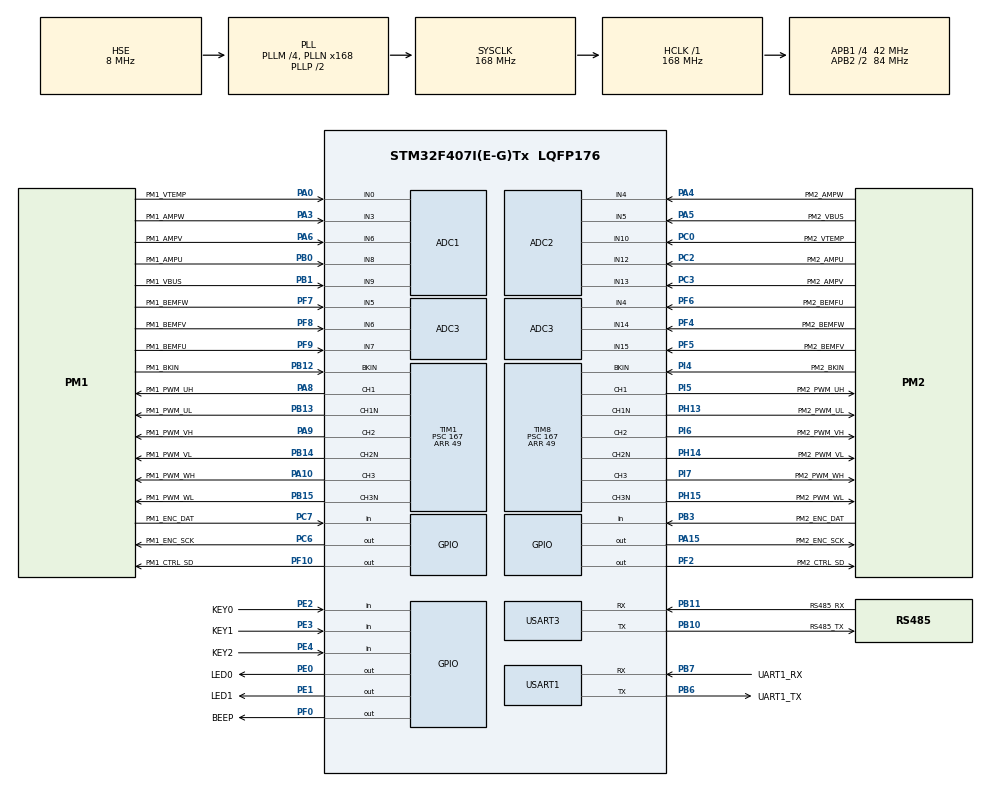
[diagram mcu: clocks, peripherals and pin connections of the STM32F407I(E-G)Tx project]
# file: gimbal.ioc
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ADC1.Channel-0\#ChannelRegularConversion=ADC_CHANNEL_0
ADC1.Channel-15\#ChannelInjectedConversion=ADC_CHANNEL_8
ADC1.Channel-16\#ChannelInjectedConversion=ADC_CHANNEL_6
ADC1.Channel-18\#ChannelInjectedConversion=ADC_CHANNEL_3
ADC1.Channel-8\#ChannelRegularConversion=ADC_CHANNEL_9
ADC1.ClockPrescaler=ADC_CLOCK_SYNC_PCLK_DIV4
ADC1.ContinuousConvMode=DISABLE
ADC1.DMAContinuousRequests=ENABLE
ADC1.EOCSelection=ADC_EOC_SEQ_CONV
ADC1.ExternalTrigConv=ADC_SOFTWARE_START
ADC1.ExternalTrigConvEdge=ADC_EXTERNALTRIGCONVEDGE_NONE
ADC1.ExternalTrigInjecConv=ADC_EXTERNALTRIGINJECCONV_T1_CC4
ADC1.InjNumberOfConversion=3
ADC1.InjectedOffset-15\#ChannelInjectedConversion=0
ADC1.InjectedOffset-16\#ChannelInjectedConversion=0
ADC1.InjectedOffset-18\#ChannelInjectedConversion=0
ADC1.InjectedRank-15\#ChannelInjectedConversion=1
ADC1.InjectedRank-16\#ChannelInjectedConversion=2
ADC1.InjectedRank-18\#ChannelInjectedConversion=3
ADC1.NbrOfConversion=2
ADC1.NbrOfConversionFlag=1
ADC1.Rank-0\#ChannelRegularConversion=1
ADC1.Rank-8\#ChannelRegularConversion=2
ADC1.SamplingTime-0\#ChannelRegularConversion=ADC_SAMPLETIME_56CYCLES
ADC1.SamplingTime-15\#ChannelInjectedConversion=ADC_SAMPLETIME_15CYCLES
ADC1.SamplingTime-16\#ChannelInjectedConversion=ADC_SAMPLETIME_15CYCLES
ADC1.SamplingTime-18\#ChannelInjectedConversion=ADC_SAMPLETIME_15CYCLES
ADC1.SamplingTime-8\#ChannelRegularConversion=ADC_SAMPLETIME_56CYCLES
ADC1.ScanConvMode=ENABLE
ADC1.master=1
ADC2.Channel-0\#ChannelRegularConversion=ADC_CHANNEL_10
ADC2.Channel-1\#ChannelRegularConversion=ADC_CHANNEL_5
ADC2.Channel-3\#ChannelInjectedConversion=ADC_CHANNEL_12
ADC2.Channel-4\#ChannelInjectedConversion=ADC_CHANNEL_13
ADC2.Channel-5\#ChannelInjectedConversion=ADC_CHANNEL_4
ADC2.ClockPrescaler=ADC_CLOCK_SYNC_PCLK_DIV4
ADC2.ContinuousConvMode=DISABLE
ADC2.DMAContinuousRequests=ENABLE
ADC2.EOCSelection=ADC_EOC_SEQ_CONV
ADC2.ExternalTrigConv=ADC_SOFTWARE_START
ADC2.ExternalTrigInjecConv=ADC_EXTERNALTRIGINJECCONV_T8_CC4
ADC2.InjNumberOfConversion=3
ADC2.InjectedOffset-3\#ChannelInjectedConversion=0
ADC2.InjectedOffset-4\#ChannelInjectedConversion=0
ADC2.InjectedOffset-5\#ChannelInjectedConversion=0
ADC2.InjectedRank-3\#ChannelInjectedConversion=1
ADC2.InjectedRank-4\#ChannelInjectedConversion=2
ADC2.InjectedRank-5\#ChannelInjectedConversion=3
ADC2.NbrOfConversion=2
ADC2.NbrOfConversionFlag=1
ADC2.Rank-0\#ChannelRegularConversion=1
ADC2.Rank-1\#ChannelRegularConversion=2
ADC2.SamplingTime-0\#ChannelRegularConversion=ADC_SAMPLETIME_56CYCLES
ADC2.SamplingTime-1\#ChannelRegularConversion=ADC_SAMPLETIME_56CYCLES
ADC2.SamplingTime-3\#ChannelInjectedConversion=ADC_SAMPLETIME_15CYCLES
ADC2.SamplingTime-4\#ChannelInjectedConversion=ADC_SAMPLETIME_15CYCLES
ADC2.SamplingTime-5\#ChannelInjectedConversion=ADC_SAMPLETIME_15CYCLES
ADC2.ScanConvMode=ENABLE
ADC3.Channel-0\#ChannelRegularConversion=ADC_CHANNEL_4
ADC3.Channel-1\#ChannelRegularConversion=ADC_CHANNEL_5
ADC3.Channel-2\#ChannelRegularConversion=ADC_CHANNEL_6
ADC3.Channel-3\#ChannelRegularConversion=ADC_CHANNEL_7
ADC3.Channel-4\#ChannelRegularConversion=ADC_CHANNEL_14
ADC3.Channel-5\#ChannelRegularConversion=ADC_CHANNEL_15
ADC3.ClockPrescaler=ADC_CLOCK_SYNC_PCLK_DIV4
ADC3.ContinuousConvMode=DISABLE
ADC3.DMAContinuousRequests=ENABLE
ADC3.EOCSelection=ADC_EOC_SEQ_CONV
ADC3.ExternalTrigConv=ADC_SOFTWARE_START
ADC3.NbrOfConversion=6
ADC3.NbrOfConversionFlag=1
ADC3.Rank-0\#ChannelRegularConversion=1
ADC3.Rank-1\#ChannelRegularConversion=2
ADC3.Rank-2\#ChannelRegularConversion=3
ADC3.Rank-3\#ChannelRegularConversion=4
ADC3.Rank-4\#ChannelRegularConversion=5
ADC3.Rank-5\#ChannelRegularConversion=6
ADC3.SamplingTime-0\#ChannelRegularConversion=ADC_SAMPLETIME_144CYCLES
ADC3.SamplingTime-1\#ChannelRegularConversion=ADC_SAMPLETIME_144CYCLES
ADC3.SamplingTime-2\#ChannelRegularConversion=ADC_SAMPLETIME_144CYCLES
ADC3.SamplingTime-3\#ChannelRegularConversion=ADC_SAMPLETIME_144CYCLES
ADC3.SamplingTime-4\#ChannelRegularConversion=ADC_SAMPLETIME_144CYCLES
ADC3.SamplingTime-5\#ChannelRegularConversion=ADC_SAMPLETIME_144CYCLES
ADC3.ScanConvMode=ENABLE
Dma.ADC1.0.Direction=DMA_PERIPH_TO_MEMORY
Dma.ADC1.0.FIFOMode=DMA_FIFOMODE_DISABLE
Dma.ADC1.0.Instance=DMA2_Stream0
Dma.ADC1.0.MemDataAlignment=DMA_MDATAALIGN_HALFWORD
Dma.ADC1.0.MemInc=DMA_MINC_ENABLE
Dma.ADC1.0.Mode=DMA_CIRCULAR
Dma.ADC1.0.PeriphDataAlignment=DMA_PDATAALIGN_HALFWORD
Dma.ADC1.0.PeriphInc=DMA_PINC_DISABLE
Dma.ADC1.0.Priority=DMA_PRIORITY_LOW
Dma.ADC2.1.Direction=DMA_PERIPH_TO_MEMORY
Dma.ADC2.1.FIFOMode=DMA_FIFOMODE_DISABLE
Dma.ADC2.1.Instance=DMA2_Stream2
Dma.ADC2.1.MemDataAlignment=DMA_MDATAALIGN_HALFWORD
Dma.ADC2.1.MemInc=DMA_MINC_ENABLE
Dma.ADC2.1.Mode=DMA_CIRCULAR
Dma.ADC2.1.PeriphDataAlignment=DMA_PDATAALIGN_HALFWORD
Dma.ADC2.1.PeriphInc=DMA_PINC_DISABLE
Dma.ADC2.1.Priority=DMA_PRIORITY_LOW
Dma.ADC3.2.Direction=DMA_PERIPH_TO_MEMORY
Dma.ADC3.2.FIFOMode=DMA_FIFOMODE_DISABLE
Dma.ADC3.2.Instance=DMA2_Stream1
Dma.ADC3.2.MemDataAlignment=DMA_MDATAALIGN_HALFWORD
Dma.ADC3.2.MemInc=DMA_MINC_ENABLE
Dma.ADC3.2.Mode=DMA_CIRCULAR
Dma.ADC3.2.PeriphDataAlignment=DMA_PDATAALIGN_HALFWORD
Dma.ADC3.2.PeriphInc=DMA_PINC_DISABLE
Dma.ADC3.2.Priority=DMA_PRIORITY_LOW
Dma.Request0=ADC1
Dma.Request1=ADC2
Dma.Request2=ADC3
Mcu.Family=STM32F4
Mcu.Name=STM32F407I(E-G)Tx
Mcu.Package=LQFP176
NVIC.ADC_IRQn=true\:0\:0\:false\:false\:true\:true\:true\:true
NVIC.PriorityGroup=NVIC_PRIORITYGROUP_4
NVIC.TIM1_TRG_COM_TIM11_IRQn=true\:0\:0\:false\:false\:true\:true\:true\:true
NVIC.TIM7_IRQn=true\:0\:0\:false\:false\:true\:true\:true\:true
NVIC.TIM8_TRG_COM_TIM14_IRQn=true\:0\:0\:false\:false\:true\:true\:true\:true
PA0-WKUP.GPIO_Label=PM1_VTEMP
PA0-WKUP.Signal=ADCx_IN0
PA10.GPIO_Label=PM1_PWM_WH
PA10.GPIO_Speed=GPIO_SPEED_FREQ_HIGH
PA10.Signal=S_TIM1_CH3
PA13.Mode=Serial_Wire
PA13.Signal=SYS_JTMS-SWDIO
PA14.Mode=Serial_Wire
PA14.Signal=SYS_JTCK-SWCLK
PA15.GPIO_Label=PM2_ENC_SCK
PA15.GPIO_PuPd=GPIO_PULLUP
PA15.GPIO_Speed=GPIO_SPEED_FREQ_VERY_HIGH
PA15.PinState=GPIO_PIN_SET
PA15.Signal=GPIO_Output
PA3.GPIO_Label=PM1_AMPW
PA3.Signal=ADCx_IN3
PA4.GPIO_Label=PM2_AMPW
PA4.Signal=ADCx_IN4
PA5.GPIO_Label=PM2_VBUS
PA5.Signal=ADCx_IN5
PA6.GPIO_Label=PM1_AMPV
PA6.Signal=ADCx_IN6
PA8.GPIO_Label=PM1_PWM_UH
PA8.GPIO_Speed=GPIO_SPEED_FREQ_HIGH
PA8.Signal=S_TIM1_CH1
PA9.GPIO_Label=PM1_PWM_VH
PA9.GPIO_Speed=GPIO_SPEED_FREQ_HIGH
PA9.Signal=S_TIM1_CH2
PB0.GPIO_Label=PM1_AMPU
PB0.Signal=ADCx_IN8
PB1.GPIO_Label=PM1_VBUS
PB1.Signal=ADCx_IN9
PB10.GPIO_Label=RS485_TX
PB10.Mode=Asynchronous
PB10.Signal=USART3_TX
PB11.GPIO_Label=RS485_RX
PB11.Mode=Asynchronous
PB11.Signal=USART3_RX
PB12.GPIO_Label=PM1_BKIN
PB12.Mode=Activate-Break-Input
PB12.Signal=TIM1_BKIN
PB13.GPIO_Label=PM1_PWM_UL
PB13.GPIO_Speed=GPIO_SPEED_FREQ_HIGH
PB13.Mode=PWM Generation1 CH1 CH1N
PB13.Signal=TIM1_CH1N
PB14.GPIO_Label=PM1_PWM_VL
PB14.GPIO_Speed=GPIO_SPEED_FREQ_HIGH
PB14.Mode=PWM Generation2 CH2 CH2N
PB14.Signal=TIM1_CH2N
PB15.GPIO_Label=PM1_PWM_WL
PB15.GPIO_Speed=GPIO_SPEED_FREQ_HIGH
PB15.Mode=PWM Generation3 CH3 CH3N
PB15.Signal=TIM1_CH3N
PB3.GPIO_Label=PM2_ENC_DAT
PB3.GPIO_PuPd=GPIO_NOPULL
PB3.Signal=GPIO_Input
PB6.GPIO_Label=UART1_TX
PB6.Mode=Asynchronous
PB6.Signal=USART1_TX
PB7.GPIO_Label=UART1_RX
PB7.Mode=Asynchronous
PB7.Signal=USART1_RX
PC0.GPIO_Label=PM2_VTEMP
PC0.Signal=ADCx_IN10
PC2.GPIO_Label=PM2_AMPU
PC2.Signal=ADCx_IN12
PC3.GPIO_Label=PM2_AMPV
PC3.Signal=ADCx_IN13
PC6.GPIO_Label=PM1_ENC_SCK
PC6.GPIO_PuPd=GPIO_PULLUP
PC6.GPIO_Speed=GPIO_SPEED_FREQ_VERY_HIGH
PC6.PinState=GPIO_PIN_SET
PC6.Signal=GPIO_Output
PC7.GPIO_Label=PM1_ENC_DAT
PC7.GPIO_PuPd=GPIO_NOPULL
PC7.Signal=GPIO_Input
PE0.GPIO_Label=LED0
PE0.GPIO_PuPd=GPIO_PULLUP
PE0.Signal=GPIO_Output
PE1.GPIO_Label=LED1
PE1.GPIO_PuPd=GPIO_PULLUP
PE1.Signal=GPIO_Output
PE2.GPIO_Label=KEY0
PE2.GPIO_PuPd=GPIO_PULLUP
PE2.Signal=GPIO_Input
PE3.GPIO_Label=KEY1
PE3.GPIO_PuPd=GPIO_PULLUP
PE3.Signal=GPIO_Input
PE4.GPIO_Label=KEY2
PE4.GPIO_PuPd=GPIO_PULLUP
PE4.Signal=GPIO_Input
PF0.GPIO_Label=BEEP
PF0.GPIO_PuPd=GPIO_PULLDOWN
PF0.Signal=GPIO_Output
PF10.GPIO_Label=PM1_CTRL_SD
PF10.GPIO_PuPd=GPIO_PULLUP
PF10.GPIO_Speed=GPIO_SPEED_FREQ_LOW
PF10.Signal=GPIO_Output
PF2.GPIO_Label=PM2_CTRL_SD
PF2.GPIO_PuPd=GPIO_PULLUP
PF2.GPIO_Speed=GPIO_SPEED_FREQ_LOW
PF2.Signal=GPIO_Output
PF4.GPIO_Label=PM2_BEMFW
PF4.Mode=IN14
PF4.Signal=ADC3_IN14
PF5.GPIO_Label=PM2_BEMFV
PF5.Mode=IN15
PF5.Signal=ADC3_IN15
PF6.GPIO_Label=PM2_BEMFU
PF6.Mode=IN4
PF6.Signal=ADC3_IN4
PF7.GPIO_Label=PM1_BEMFW
PF7.Mode=IN5
PF7.Signal=ADC3_IN5
PF8.GPIO_Label=PM1_BEMFV
PF8.Mode=IN6
PF8.Signal=ADC3_IN6
PF9.GPIO_Label=PM1_BEMFU
PF9.Mode=IN7
PF9.Signal=ADC3_IN7
PH0-OSC_IN.Mode=HSE-External-Oscillator
PH0-OSC_IN.Signal=RCC_OSC_IN
PH1-OSC_OUT.Mode=HSE-External-Oscillator
PH1-OSC_OUT.Signal=RCC_OSC_OUT
PH13.GPIO_Label=PM2_PWM_UL
PH13.Mode=PWM Generation1 CH1 CH1N
PH13.Signal=TIM8_CH1N
PH14.GPIO_Label=PM2_PWM_VL
PH14.Mode=PWM Generation2 CH2 CH2N
PH14.Signal=TIM8_CH2N
PH15.GPIO_Label=PM2_PWM_WL
PH15.Mode=PWM Generation3 CH3 CH3N
PH15.Signal=TIM8_CH3N
PI4.GPIO_Label=PM2_BKIN
PI4.Mode=Activate-Break-Input
PI4.Signal=TIM8_BKIN
PI5.GPIO_Label=PM2_PWM_UH
PI5.Signal=S_TIM8_CH1
PI6.GPIO_Label=PM2_PWM_VH
PI6.Signal=S_TIM8_CH2
PI7.GPIO_Label=PM2_PWM_WH
PI7.Signal=S_TIM8_CH3
ProjectManager.HeapSize=0x200
ProjectManager.StackSize=0x400
ProjectManager.TargetToolchain=CMake
RCC.48MHZClocksFreq_Value=84000000
RCC.AHBFreq_Value=168000000
RCC.APB1CLKDivider=RCC_HCLK_DIV4
RCC.APB1Freq_Value=42000000
RCC.APB1TimFreq_Value=84000000
RCC.APB2CLKDivider=RCC_HCLK_DIV2
RCC.APB2Freq_Value=84000000
RCC.APB2TimFreq_Value=168000000
RCC.CortexFreq_Value=168000000
RCC.HCLKFreq_Value=168000000
RCC.HSE_VALUE=8000000
RCC.HSI_VALUE=16000000
RCC.LSE_VALUE=32768
RCC.PLLM=4
RCC.PLLN=168
RCC.PLLSourceVirtual=RCC_PLLSOURCE_HSE
RCC.SYSCLKFreq_VALUE=168000000
RCC.SYSCLKSource=RCC_SYSCLKSOURCE_PLLCLK
RCC.VCOOutputFreq_Value=336000000
SH.ADCx_IN0.0=ADC1_IN0,IN0
SH.ADCx_IN10.0=ADC2_IN10,IN10
SH.ADCx_IN12.0=ADC2_IN12,IN12
SH.ADCx_IN13.0=ADC2_IN13,IN13
SH.ADCx_IN3.0=ADC1_IN3,IN3
SH.ADCx_IN4.0=ADC2_IN4,IN4
SH.ADCx_IN5.0=ADC2_IN5,IN5
SH.ADCx_IN6.0=ADC1_IN6,IN6
SH.ADCx_IN8.0=ADC1_IN8,IN8
SH.ADCx_IN9.0=ADC1_IN9,IN9
SH.S_TIM1_CH1.0=TIM1_CH1,PWM Generation1 CH1 CH1N
SH.S_TIM1_CH2.0=TIM1_CH2,PWM Generation2 CH2 CH2N
SH.S_TIM1_CH3.0=TIM1_CH3,PWM Generation3 CH3 CH3N
SH.S_TIM8_CH1.0=TIM8_CH1,PWM Generation1 CH1 CH1N
SH.S_TIM8_CH2.0=TIM8_CH2,PWM Generation2 CH2 CH2N
SH.S_TIM8_CH3.0=TIM8_CH3,PWM Generation3 CH3 CH3N
TIM1.AutoReloadPreload=TIM_AUTORELOAD_PRELOAD_ENABLE
TIM1.AutomaticOutput=TIM_AUTOMATICOUTPUT_DISABLE
TIM1.Channel-Output\ Compare4\ No\ Output=TIM_CHANNEL_4
TIM1.Channel-PWM\ Generation1\ CH1\ CH1N=TIM_CHANNEL_1
TIM1.Channel-PWM\ Generation2\ CH2\ CH2N=TIM_CHANNEL_2
TIM1.Channel-PWM\ Generation3\ CH3\ CH3N=TIM_CHANNEL_3
TIM1.CounterMode=TIM_COUNTERMODE_CENTERALIGNED1
TIM1.DeadTime=100
TIM1.LockLevel=TIM_LOCKLEVEL_OFF
TIM1.OCMode_4=TIM_OCMODE_ACTIVE
TIM1.OCMode_PWM-PWM\ Generation1\ CH1\ CH1N=TIM_OCMODE_PWM2
TIM1.OCMode_PWM-PWM\ Generation2\ CH2\ CH2N=TIM_OCMODE_PWM2
TIM1.OCMode_PWM-PWM\ Generation3\ CH3\ CH3N=TIM_OCMODE_PWM2
TIM1.OCNIdleState_2=TIM_OCNIDLESTATE_RESET
TIM1.OffStateIDLEMode=TIM_OSSI_DISABLE
TIM1.OffStateRunMode=TIM_OSSR_DISABLE
TIM1.Period=49
TIM1.Prescaler=167
TIM1.Pulse-Output\ Compare4\ No\ Output=45
TIM1.Pulse-PWM\ Generation1\ CH1\ CH1N=0
TIM1.Pulse-PWM\ Generation2\ CH2\ CH2N=0
TIM1.RepetitionCounter=1
TIM1.TIM_MasterOutputTrigger=TIM_TRGO_OC4REF
TIM1.TIM_MasterSlaveMode=TIM_MASTERSLAVEMODE_DISABLE
TIM6.AutoReloadPreload=TIM_AUTORELOAD_PRELOAD_ENABLE
TIM6.Period=100-1
TIM6.Prescaler=84-1
TIM7.AutoReloadPreload=TIM_AUTORELOAD_PRELOAD_ENABLE
TIM7.Period=100-1
TIM7.Prescaler=84-1
TIM8.AutoReloadPreload=TIM_AUTORELOAD_PRELOAD_ENABLE
TIM8.AutomaticOutput=TIM_AUTOMATICOUTPUT_DISABLE
TIM8.Channel-Output\ Compare4\ No\ Output=TIM_CHANNEL_4
TIM8.Channel-PWM\ Generation1\ CH1\ CH1N=TIM_CHANNEL_1
TIM8.Channel-PWM\ Generation2\ CH2\ CH2N=TIM_CHANNEL_2
TIM8.Channel-PWM\ Generation3\ CH3\ CH3N=TIM_CHANNEL_3
TIM8.CounterMode=TIM_COUNTERMODE_CENTERALIGNED1
TIM8.DeadTime=100
TIM8.OCMode_4=TIM_OCMODE_ACTIVE
TIM8.OCMode_PWM-PWM\ Generation1\ CH1\ CH1N=TIM_OCMODE_PWM2
TIM8.OCMode_PWM-PWM\ Generation2\ CH2\ CH2N=TIM_OCMODE_PWM2
TIM8.OCMode_PWM-PWM\ Generation3\ CH3\ CH3N=TIM_OCMODE_PWM2
TIM8.OffStateIDLEMode=TIM_OSSI_DISABLE
TIM8.OffStateRunMode=TIM_OSSR_DISABLE
TIM8.Period=49
TIM8.Prescaler=167
TIM8.Pulse-Output\ Compare4\ No\ Output=45
TIM8.RepetitionCounter=1
TIM8.TIM_MasterOutputTrigger=TIM_TRGO_OC4REF
USART1.VirtualMode=VM_ASYNC
USART3.VirtualMode=VM_ASYNC
VP_CRC_VS_CRC.Mode=CRC_Activate
VP_TIM1_VS_ClockSourceINT.Mode=Internal
VP_TIM1_VS_no_output4.Mode=Output Compare4 No Output
VP_TIM6_VS_ClockSourceINT.Mode=Enable_Timer
VP_TIM7_VS_ClockSourceINT.Mode=Enable_Timer
VP_TIM8_VS_ClockSourceINT.Mode=Internal
VP_TIM8_VS_no_output4.Mode=Output Compare4 No Output
board=custom

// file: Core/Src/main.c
/* USER CODE BEGIN Header */
/**
  ******************************************************************************
  * @file           : main.c
  * @brief          : Main program body
  ******************************************************************************
  * @attention
  *
  * Copyright (c) 2026 STMicroelectronics.
  * All rights reserved.
  *
  * This software is licensed under terms that can be found in the LICENSE file
  * in the root directory of this software component.
  * If no LICENSE file comes with this software, it is provided AS-IS.
  *
  ******************************************************************************
  */
/* USER CODE END Header */
#include "main.h"

/* USER CODE BEGIN Includes */
#include "app.h"
#include "foc.h"
#include "control.h"
#include "biss.h"
/* USER CODE END Includes */

ADC_HandleTypeDef hadc1;
ADC_HandleTypeDef hadc2;
ADC_HandleTypeDef hadc3;
DMA_HandleTypeDef hdma_adc1;
DMA_HandleTypeDef hdma_adc2;
DMA_HandleTypeDef hdma_adc3;

CRC_HandleTypeDef hcrc;

TIM_HandleTypeDef htim1;
TIM_HandleTypeDef htim6;
TIM_HandleTypeDef htim7;
TIM_HandleTypeDef htim8;

UART_HandleTypeDef huart1;
UART_HandleTypeDef huart3;

void SystemClock_Config(void);
static void MX_GPIO_Init(void);
static void MX_DMA_Init(void);
static void MX_USART1_UART_Init(void);
static void MX_ADC1_Init(void);
static void MX_ADC2_Init(void);
static void MX_ADC3_Init(void);
static void MX_TIM1_Init(void);
static void MX_TIM8_Init(void);
static void MX_USART3_UART_Init(void);
static void MX_TIM7_Init(void);
static void MX_TIM6_Init(void);
static void MX_CRC_Init(void);
/* USER CODE BEGIN PFP */
uint8_t KEY_Scan(uint16_t GPIO_Pin);  /************************** LED***********************/

/* USER CODE END PFP */

int main(void)
{

  /* MCU Configuration--------------------------------------------------------*/

  /* Reset of all peripherals, Initializes the Flash interface and the Systick. */
  HAL_Init();

  /* Configure the system clock */
  SystemClock_Config();

  /* Initialize all configured peripherals */
  MX_GPIO_Init();
  MX_DMA_Init();
  MX_USART1_UART_Init();
  MX_ADC1_Init();
  MX_ADC2_Init();
  MX_ADC3_Init();
  MX_TIM1_Init();
  MX_TIM8_Init();
  MX_USART3_UART_Init();
  MX_TIM7_Init();
  MX_TIM6_Init();
  MX_CRC_Init();
  /* USER CODE BEGIN 2 */

  Motor_Init();
  setup();

//  SVPWM_OpenLoop_Example();

  /* USER CODE END 2 */

  /* Infinite loop */
  while (1)
  {

    /* USER CODE BEGIN 3 */

    motor1.theta_m =MP55_ReadFrame(&encoder_motor1);        // 编码器数据（机械角度）

  }
  /* USER CODE END 3 */
}

void SystemClock_Config(void)
{
  RCC_OscInitTypeDef RCC_OscInitStruct = {0};
  RCC_ClkInitTypeDef RCC_ClkInitStruct = {0};

  /** Configure the main internal regulator output voltage
  */
  __HAL_RCC_PWR_CLK_ENABLE();
  __HAL_PWR_VOLTAGESCALING_CONFIG(PWR_REGULATOR_VOLTAGE_SCALE1);

  /** Initializes the RCC Oscillators according to the specified parameters
  * in the RCC_OscInitTypeDef structure.
  */
  RCC_OscInitStruct.OscillatorType = RCC_OSCILLATORTYPE_HSE;
  RCC_OscInitStruct.HSEState = RCC_HSE_ON;
  RCC_OscInitStruct.PLL.PLLState = RCC_PLL_ON;
  RCC_OscInitStruct.PLL.PLLSource = RCC_PLLSOURCE_HSE;
  RCC_OscInitStruct.PLL.PLLM = 4;
  RCC_OscInitStruct.PLL.PLLN = 168;
  RCC_OscInitStruct.PLL.PLLP = RCC_PLLP_DIV2;
  RCC_OscInitStruct.PLL.PLLQ = 4;
  if (HAL_RCC_OscConfig(&RCC_OscInitStruct) != HAL_OK)
  {
    Error_Handler();
  }

  /** Initializes the CPU, AHB and APB buses clocks
  */
  RCC_ClkInitStruct.ClockType = RCC_CLOCKTYPE_HCLK|RCC_CLOCKTYPE_SYSCLK
                              |RCC_CLOCKTYPE_PCLK1|RCC_CLOCKTYPE_PCLK2;
  RCC_ClkInitStruct.SYSCLKSource = RCC_SYSCLKSOURCE_PLLCLK;
  RCC_ClkInitStruct.AHBCLKDivider = RCC_SYSCLK_DIV1;
  RCC_ClkInitStruct.APB1CLKDivider = RCC_HCLK_DIV4;
  RCC_ClkInitStruct.APB2CLKDivider = RCC_HCLK_DIV2;

  if (HAL_RCC_ClockConfig(&RCC_ClkInitStruct, FLASH_LATENCY_5) != HAL_OK)
  {
    Error_Handler();
  }
}

static void MX_ADC1_Init(void)
{

  ADC_ChannelConfTypeDef sConfig = {0};
  ADC_InjectionConfTypeDef sConfigInjected = {0};

  /** Configure the global features of the ADC (Clock, Resolution, Data Alignment and number of conversion)
  */
  hadc1.Instance = ADC1;
  hadc1.Init.ClockPrescaler = ADC_CLOCK_SYNC_PCLK_DIV4;
  hadc1.Init.Resolution = ADC_RESOLUTION_12B;
  hadc1.Init.ScanConvMode = ENABLE;
  hadc1.Init.ContinuousConvMode = DISABLE;
  hadc1.Init.DiscontinuousConvMode = DISABLE;
  hadc1.Init.ExternalTrigConvEdge = ADC_EXTERNALTRIGCONVEDGE_NONE;
  hadc1.Init.ExternalTrigConv = ADC_SOFTWARE_START;
  hadc1.Init.DataAlign = ADC_DATAALIGN_RIGHT;
  hadc1.Init.NbrOfConversion = 2;
  hadc1.Init.DMAContinuousRequests = ENABLE;
  hadc1.Init.EOCSelection = ADC_EOC_SEQ_CONV;
  if (HAL_ADC_Init(&hadc1) != HAL_OK)
  {
    Error_Handler();
  }

  /** Configure for the selected ADC regular channel its corresponding rank in the sequencer and its sample time.
  */
  sConfig.Channel = ADC_CHANNEL_0;
  sConfig.Rank = 1;
  sConfig.SamplingTime = ADC_SAMPLETIME_56CYCLES;
  if (HAL_ADC_ConfigChannel(&hadc1, &sConfig) != HAL_OK)
  {
    Error_Handler();
  }

  /** Configure for the selected ADC regular channel its corresponding rank in the sequencer and its sample time.
  */
  sConfig.Channel = ADC_CHANNEL_9;
  sConfig.Rank = 2;
  if (HAL_ADC_ConfigChannel(&hadc1, &sConfig) != HAL_OK)
  {
    Error_Handler();
  }

  /** Configures for the selected ADC injected channel its corresponding rank in the sequencer and its sample time
  */
  sConfigInjected.InjectedChannel = ADC_CHANNEL_8;
  sConfigInjected.InjectedRank = 1;
  sConfigInjected.InjectedNbrOfConversion = 3;
  sConfigInjected.InjectedSamplingTime = ADC_SAMPLETIME_15CYCLES;
  sConfigInjected.ExternalTrigInjecConvEdge = ADC_EXTERNALTRIGINJECCONVEDGE_RISING;
  sConfigInjected.ExternalTrigInjecConv = ADC_EXTERNALTRIGINJECCONV_T1_CC4;
  sConfigInjected.AutoInjectedConv = DISABLE;
  sConfigInjected.InjectedDiscontinuousConvMode = DISABLE;
  sConfigInjected.InjectedOffset = 0;
  if (HAL_ADCEx_InjectedConfigChannel(&hadc1, &sConfigInjected) != HAL_OK)
  {
    Error_Handler();
  }

  /** Configures for the selected ADC injected channel its corresponding rank in the sequencer and its sample time
  */
  sConfigInjected.InjectedChannel = ADC_CHANNEL_6;
  sConfigInjected.InjectedRank = 2;
  if (HAL_ADCEx_InjectedConfigChannel(&hadc1, &sConfigInjected) != HAL_OK)
  {
    Error_Handler();
  }

  /** Configures for the selected ADC injected channel its corresponding rank in the sequencer and its sample time
  */
  sConfigInjected.InjectedChannel = ADC_CHANNEL_3;
  sConfigInjected.InjectedRank = 3;
  if (HAL_ADCEx_InjectedConfigChannel(&hadc1, &sConfigInjected) != HAL_OK)
  {
    Error_Handler();
  }

}

static void MX_ADC2_Init(void)
{

  ADC_ChannelConfTypeDef sConfig = {0};
  ADC_InjectionConfTypeDef sConfigInjected = {0};

  /** Configure the global features of the ADC (Clock, Resolution, Data Alignment and number of conversion)
  */
  hadc2.Instance = ADC2;
  hadc2.Init.ClockPrescaler = ADC_CLOCK_SYNC_PCLK_DIV4;
  hadc2.Init.Resolution = ADC_RESOLUTION_12B;
  hadc2.Init.ScanConvMode = ENABLE;
  hadc2.Init.ContinuousConvMode = DISABLE;
  hadc2.Init.DiscontinuousConvMode = DISABLE;
  hadc2.Init.ExternalTrigConvEdge = ADC_EXTERNALTRIGCONVEDGE_NONE;
  hadc2.Init.ExternalTrigConv = ADC_SOFTWARE_START;
  hadc2.Init.DataAlign = ADC_DATAALIGN_RIGHT;
  hadc2.Init.NbrOfConversion = 2;
  hadc2.Init.DMAContinuousRequests = ENABLE;
  hadc2.Init.EOCSelection = ADC_EOC_SEQ_CONV;
  if (HAL_ADC_Init(&hadc2) != HAL_OK)
  {
    Error_Handler();
  }

  /** Configure for the selected ADC regular channel its corresponding rank in the sequencer and its sample time.
  */
  sConfig.Channel = ADC_CHANNEL_10;
  sConfig.Rank = 1;
  sConfig.SamplingTime = ADC_SAMPLETIME_56CYCLES;
  if (HAL_ADC_ConfigChannel(&hadc2, &sConfig) != HAL_OK)
  {
    Error_Handler();
  }

  /** Configure for the selected ADC regular channel its corresponding rank in the sequencer and its sample time.
  */
  sConfig.Channel = ADC_CHANNEL_5;
  sConfig.Rank = 2;
  if (HAL_ADC_ConfigChannel(&hadc2, &sConfig) != HAL_OK)
  {
    Error_Handler();
  }

  /** Configures for the selected ADC injected channel its corresponding rank in the sequencer and its sample time
  */
  sConfigInjected.InjectedChannel = ADC_CHANNEL_12;
  sConfigInjected.InjectedRank = 1;
  sConfigInjected.InjectedNbrOfConversion = 3;
  sConfigInjected.InjectedSamplingTime = ADC_SAMPLETIME_15CYCLES;
  sConfigInjected.ExternalTrigInjecConvEdge = ADC_EXTERNALTRIGINJECCONVEDGE_RISING;
  sConfigInjected.ExternalTrigInjecConv = ADC_EXTERNALTRIGINJECCONV_T8_CC4;
  sConfigInjected.AutoInjectedConv = DISABLE;
  sConfigInjected.InjectedDiscontinuousConvMode = DISABLE;
  sConfigInjected.InjectedOffset = 0;
  if (HAL_ADCEx_InjectedConfigChannel(&hadc2, &sConfigInjected) != HAL_OK)
  {
    Error_Handler();
  }

  /** Configures for the selected ADC injected channel its corresponding rank in the sequencer and its sample time
  */
  sConfigInjected.InjectedChannel = ADC_CHANNEL_13;
  sConfigInjected.InjectedRank = 2;
  if (HAL_ADCEx_InjectedConfigChannel(&hadc2, &sConfigInjected) != HAL_OK)
  {
    Error_Handler();
  }

  /** Configures for the selected ADC injected channel its corresponding rank in the sequencer and its sample time
  */
  sConfigInjected.InjectedChannel = ADC_CHANNEL_4;
  sConfigInjected.InjectedRank = 3;
  if (HAL_ADCEx_InjectedConfigChannel(&hadc2, &sConfigInjected) != HAL_OK)
  {
    Error_Handler();
  }

}

static void MX_ADC3_Init(void)
{

  ADC_ChannelConfTypeDef sConfig = {0};

  /** Configure the global features of the ADC (Clock, Resolution, Data Alignment and number of conversion)
  */
  hadc3.Instance = ADC3;
  hadc3.Init.ClockPrescaler = ADC_CLOCK_SYNC_PCLK_DIV4;
  hadc3.Init.Resolution = ADC_RESOLUTION_12B;
  hadc3.Init.ScanConvMode = ENABLE;
  hadc3.Init.ContinuousConvMode = DISABLE;
  hadc3.Init.DiscontinuousConvMode = DISABLE;
  hadc3.Init.ExternalTrigConvEdge = ADC_EXTERNALTRIGCONVEDGE_NONE;
  hadc3.Init.ExternalTrigConv = ADC_SOFTWARE_START;
  hadc3.Init.DataAlign = ADC_DATAALIGN_RIGHT;
  hadc3.Init.NbrOfConversion = 6;
  hadc3.Init.DMAContinuousRequests = ENABLE;
  hadc3.Init.EOCSelection = ADC_EOC_SEQ_CONV;
  if (HAL_ADC_Init(&hadc3) != HAL_OK)
  {
    Error_Handler();
  }

  /** Configure for the selected ADC regular channel its corresponding rank in the sequencer and its sample time.
  */
  sConfig.Channel = ADC_CHANNEL_4;
  sConfig.Rank = 1;
  sConfig.SamplingTime = ADC_SAMPLETIME_144CYCLES;
  if (HAL_ADC_ConfigChannel(&hadc3, &sConfig) != HAL_OK)
  {
    Error_Handler();
  }

  /** Configure for the selected ADC regular channel its corresponding rank in the sequencer and its sample time.
  */
  sConfig.Channel = ADC_CHANNEL_5;
  sConfig.Rank = 2;
  if (HAL_ADC_ConfigChannel(&hadc3, &sConfig) != HAL_OK)
  {
    Error_Handler();
  }

  /** Configure for the selected ADC regular channel its corresponding rank in the sequencer and its sample time.
  */
  sConfig.Channel = ADC_CHANNEL_6;
  sConfig.Rank = 3;
  if (HAL_ADC_ConfigChannel(&hadc3, &sConfig) != HAL_OK)
  {
    Error_Handler();
  }

  /** Configure for the selected ADC regular channel its corresponding rank in the sequencer and its sample time.
  */
  sConfig.Channel = ADC_CHANNEL_7;
  sConfig.Rank = 4;
  if (HAL_ADC_ConfigChannel(&hadc3, &sConfig) != HAL_OK)
  {
    Error_Handler();
  }

  /** Configure for the selected ADC regular channel its corresponding rank in the sequencer and its sample time.
  */
  sConfig.Channel = ADC_CHANNEL_14;
  sConfig.Rank = 5;
  if (HAL_ADC_ConfigChannel(&hadc3, &sConfig) != HAL_OK)
  {
    Error_Handler();
  }

  /** Configure for the selected ADC regular channel its corresponding rank in the sequencer and its sample time.
  */
  sConfig.Channel = ADC_CHANNEL_15;
  sConfig.Rank = 6;
  if (HAL_ADC_ConfigChannel(&hadc3, &sConfig) != HAL_OK)
  {
    Error_Handler();
  }

}

static void MX_CRC_Init(void)
{

  hcrc.Instance = CRC;
  if (HAL_CRC_Init(&hcrc) != HAL_OK)
  {
    Error_Handler();
  }

}

static void MX_TIM1_Init(void)
{

  TIM_ClockConfigTypeDef sClockSourceConfig = {0};
  TIM_MasterConfigTypeDef sMasterConfig = {0};
  TIM_OC_InitTypeDef sConfigOC = {0};
  TIM_BreakDeadTimeConfigTypeDef sBreakDeadTimeConfig = {0};

  htim1.Instance = TIM1;
  htim1.Init.Prescaler = 167;
  htim1.Init.CounterMode = TIM_COUNTERMODE_CENTERALIGNED1;
  htim1.Init.Period = 49;
  htim1.Init.ClockDivision = TIM_CLOCKDIVISION_DIV1;
  htim1.Init.RepetitionCounter = 1;
  htim1.Init.AutoReloadPreload = TIM_AUTORELOAD_PRELOAD_ENABLE;
  if (HAL_TIM_Base_Init(&htim1) != HAL_OK)
  {
    Error_Handler();
  }
  sClockSourceConfig.ClockSource = TIM_CLOCKSOURCE_INTERNAL;
  if (HAL_TIM_ConfigClockSource(&htim1, &sClockSourceConfig) != HAL_OK)
  {
    Error_Handler();
  }
  if (HAL_TIM_PWM_Init(&htim1) != HAL_OK)
  {
    Error_Handler();
  }
  if (HAL_TIM_OC_Init(&htim1) != HAL_OK)
  {
    Error_Handler();
  }
  sMasterConfig.MasterOutputTrigger = TIM_TRGO_OC4REF;
  sMasterConfig.MasterSlaveMode = TIM_MASTERSLAVEMODE_DISABLE;
  if (HAL_TIMEx_MasterConfigSynchronization(&htim1, &sMasterConfig) != HAL_OK)
  {
    Error_Handler();
  }
  sConfigOC.OCMode = TIM_OCMODE_PWM2;
  sConfigOC.Pulse = 0;
  sConfigOC.OCPolarity = TIM_OCPOLARITY_HIGH;
  sConfigOC.OCNPolarity = TIM_OCNPOLARITY_HIGH;
  sConfigOC.OCFastMode = TIM_OCFAST_DISABLE;
  sConfigOC.OCIdleState = TIM_OCIDLESTATE_RESET;
  sConfigOC.OCNIdleState = TIM_OCNIDLESTATE_RESET;
  if (HAL_TIM_PWM_ConfigChannel(&htim1, &sConfigOC, TIM_CHANNEL_1) != HAL_OK)
  {
    Error_Handler();
  }
  if (HAL_TIM_PWM_ConfigChannel(&htim1, &sConfigOC, TIM_CHANNEL_2) != HAL_OK)
  {
    Error_Handler();
  }
  if (HAL_TIM_PWM_ConfigChannel(&htim1, &sConfigOC, TIM_CHANNEL_3) != HAL_OK)
  {
    Error_Handler();
  }
  sConfigOC.OCMode = TIM_OCMODE_ACTIVE;
  sConfigOC.Pulse = 45;
  if (HAL_TIM_OC_ConfigChannel(&htim1, &sConfigOC, TIM_CHANNEL_4) != HAL_OK)
  {
    Error_Handler();
  }
  sBreakDeadTimeConfig.OffStateRunMode = TIM_OSSR_DISABLE;
  sBreakDeadTimeConfig.OffStateIDLEMode = TIM_OSSI_DISABLE;
  sBreakDeadTimeConfig.LockLevel = TIM_LOCKLEVEL_OFF;
  sBreakDeadTimeConfig.DeadTime = 100;
  sBreakDeadTimeConfig.BreakState = TIM_BREAK_ENABLE;
  sBreakDeadTimeConfig.BreakPolarity = TIM_BREAKPOLARITY_HIGH;
  sBreakDeadTimeConfig.AutomaticOutput = TIM_AUTOMATICOUTPUT_DISABLE;
  if (HAL_TIMEx_ConfigBreakDeadTime(&htim1, &sBreakDeadTimeConfig) != HAL_OK)
  {
    Error_Handler();
  }
  HAL_TIM_MspPostInit(&htim1);

}

static void MX_TIM6_Init(void)
{

  TIM_MasterConfigTypeDef sMasterConfig = {0};

  htim6.Instance = TIM6;
  htim6.Init.Prescaler = 84-1;
  htim6.Init.CounterMode = TIM_COUNTERMODE_UP;
  htim6.Init.Period = 100-1;
  htim6.Init.AutoReloadPreload = TIM_AUTORELOAD_PRELOAD_ENABLE;
  if (HAL_TIM_Base_Init(&htim6) != HAL_OK)
  {
    Error_Handler();
  }
  sMasterConfig.MasterOutputTrigger = TIM_TRGO_RESET;
  sMasterConfig.MasterSlaveMode = TIM_MASTERSLAVEMODE_DISABLE;
  if (HAL_TIMEx_MasterConfigSynchronization(&htim6, &sMasterConfig) != HAL_OK)
  {
    Error_Handler();
  }

}

static void MX_TIM7_Init(void)
{

  TIM_MasterConfigTypeDef sMasterConfig = {0};

  htim7.Instance = TIM7;
  htim7.Init.Prescaler = 84-1;
  htim7.Init.CounterMode = TIM_COUNTERMODE_UP;
  htim7.Init.Period = 100-1;
  htim7.Init.AutoReloadPreload = TIM_AUTORELOAD_PRELOAD_ENABLE;
  if (HAL_TIM_Base_Init(&htim7) != HAL_OK)
  {
    Error_Handler();
  }
  sMasterConfig.MasterOutputTrigger = TIM_TRGO_RESET;
  sMasterConfig.MasterSlaveMode = TIM_MASTERSLAVEMODE_DISABLE;
  if (HAL_TIMEx_MasterConfigSynchronization(&htim7, &sMasterConfig) != HAL_OK)
  {
    Error_Handler();
  }

}

static void MX_TIM8_Init(void)
{

  TIM_ClockConfigTypeDef sClockSourceConfig = {0};
  TIM_MasterConfigTypeDef sMasterConfig = {0};
  TIM_OC_InitTypeDef sConfigOC = {0};
  TIM_BreakDeadTimeConfigTypeDef sBreakDeadTimeConfig = {0};

  htim8.Instance = TIM8;
  htim8.Init.Prescaler = 167;
  htim8.Init.CounterMode = TIM_COUNTERMODE_CENTERALIGNED1;
  htim8.Init.Period = 49;
  htim8.Init.ClockDivision = TIM_CLOCKDIVISION_DIV1;
  htim8.Init.RepetitionCounter = 1;
  htim8.Init.AutoReloadPreload = TIM_AUTORELOAD_PRELOAD_ENABLE;
  if (HAL_TIM_Base_Init(&htim8) != HAL_OK)
  {
    Error_Handler();
  }
  sClockSourceConfig.ClockSource = TIM_CLOCKSOURCE_INTERNAL;
  if (HAL_TIM_ConfigClockSource(&htim8, &sClockSourceConfig) != HAL_OK)
  {
    Error_Handler();
  }
  if (HAL_TIM_PWM_Init(&htim8) != HAL_OK)
  {
    Error_Handler();
  }
  if (HAL_TIM_OC_Init(&htim8) != HAL_OK)
  {
    Error_Handler();
  }
  sMasterConfig.MasterOutputTrigger = TIM_TRGO_OC4REF;
  sMasterConfig.MasterSlaveMode = TIM_MASTERSLAVEMODE_DISABLE;
  if (HAL_TIMEx_MasterConfigSynchronization(&htim8, &sMasterConfig) != HAL_OK)
  {
    Error_Handler();
  }
  sConfigOC.OCMode = TIM_OCMODE_PWM2;
  sConfigOC.Pulse = 0;
  sConfigOC.OCPolarity = TIM_OCPOLARITY_HIGH;
  sConfigOC.OCNPolarity = TIM_OCNPOLARITY_HIGH;
  sConfigOC.OCFastMode = TIM_OCFAST_DISABLE;
  sConfigOC.OCIdleState = TIM_OCIDLESTATE_RESET;
  sConfigOC.OCNIdleState = TIM_OCNIDLESTATE_RESET;
  if (HAL_TIM_PWM_ConfigChannel(&htim8, &sConfigOC, TIM_CHANNEL_1) != HAL_OK)
  {
    Error_Handler();
  }
  if (HAL_TIM_PWM_ConfigChannel(&htim8, &sConfigOC, TIM_CHANNEL_2) != HAL_OK)
  {
    Error_Handler();
  }
  if (HAL_TIM_PWM_ConfigChannel(&htim8, &sConfigOC, TIM_CHANNEL_3) != HAL_OK)
  {
    Error_Handler();
  }
  sConfigOC.OCMode = TIM_OCMODE_ACTIVE;
  sConfigOC.Pulse = 45;
  if (HAL_TIM_OC_ConfigChannel(&htim8, &sConfigOC, TIM_CHANNEL_4) != HAL_OK)
  {
    Error_Handler();
  }
  sBreakDeadTimeConfig.OffStateRunMode = TIM_OSSR_DISABLE;
  sBreakDeadTimeConfig.OffStateIDLEMode = TIM_OSSI_DISABLE;
  sBreakDeadTimeConfig.LockLevel = TIM_LOCKLEVEL_OFF;
  sBreakDeadTimeConfig.DeadTime = 100;
  sBreakDeadTimeConfig.BreakState = TIM_BREAK_ENABLE;
  sBreakDeadTimeConfig.BreakPolarity = TIM_BREAKPOLARITY_HIGH;
  sBreakDeadTimeConfig.AutomaticOutput = TIM_AUTOMATICOUTPUT_DISABLE;
  if (HAL_TIMEx_ConfigBreakDeadTime(&htim8, &sBreakDeadTimeConfig) != HAL_OK)
  {
    Error_Handler();
  }
  HAL_TIM_MspPostInit(&htim8);

}

static void MX_USART1_UART_Init(void)
{

  huart1.Instance = USART1;
  huart1.Init.BaudRate = 115200;
  huart1.Init.WordLength = UART_WORDLENGTH_8B;
  huart1.Init.StopBits = UART_STOPBITS_1;
  huart1.Init.Parity = UART_PARITY_NONE;
  huart1.Init.Mode = UART_MODE_TX_RX;
  huart1.Init.HwFlowCtl = UART_HWCONTROL_NONE;
  huart1.Init.OverSampling = UART_OVERSAMPLING_16;
  if (HAL_UART_Init(&huart1) != HAL_OK)
  {
    Error_Handler();
  }

}

static void MX_USART3_UART_Init(void)
{

  huart3.Instance = USART3;
  huart3.Init.BaudRate = 115200;
  huart3.Init.WordLength = UART_WORDLENGTH_8B;
  huart3.Init.StopBits = UART_STOPBITS_1;
  huart3.Init.Parity = UART_PARITY_NONE;
  huart3.Init.Mode = UART_MODE_TX_RX;
  huart3.Init.HwFlowCtl = UART_HWCONTROL_NONE;
  huart3.Init.OverSampling = UART_OVERSAMPLING_16;
  if (HAL_UART_Init(&huart3) != HAL_OK)
  {
    Error_Handler();
  }

}

static void MX_DMA_Init(void)
{

  /* DMA controller clock enable */
  __HAL_RCC_DMA2_CLK_ENABLE();

}

static void MX_GPIO_Init(void)
{
  GPIO_InitTypeDef GPIO_InitStruct = {0};

  /* GPIO Ports Clock Enable */
  __HAL_RCC_GPIOE_CLK_ENABLE();
  __HAL_RCC_GPIOF_CLK_ENABLE();
  __HAL_RCC_GPIOH_CLK_ENABLE();
  __HAL_RCC_GPIOC_CLK_ENABLE();
  __HAL_RCC_GPIOA_CLK_ENABLE();
  __HAL_RCC_GPIOB_CLK_ENABLE();
  __HAL_RCC_GPIOI_CLK_ENABLE();

  /*Configure GPIO pin Output Level */
  HAL_GPIO_WritePin(GPIOF, BEEP_Pin|PM2_CTRL_SD_Pin|PM1_CTRL_SD_Pin, GPIO_PIN_RESET);

  /*Configure GPIO pin Output Level */
  HAL_GPIO_WritePin(PM1_ENC_SCK_GPIO_Port, PM1_ENC_SCK_Pin, GPIO_PIN_SET);

  /*Configure GPIO pin Output Level */
  HAL_GPIO_WritePin(PM2_ENC_SCK_GPIO_Port, PM2_ENC_SCK_Pin, GPIO_PIN_SET);

  /*Configure GPIO pin Output Level */
  HAL_GPIO_WritePin(GPIOE, LED0_Pin|LED1_Pin, GPIO_PIN_RESET);

  /*Configure GPIO pins : KEY0_Pin KEY1_Pin KEY2_Pin */
  GPIO_InitStruct.Pin = KEY0_Pin|KEY1_Pin|KEY2_Pin;
  GPIO_InitStruct.Mode = GPIO_MODE_INPUT;
  GPIO_InitStruct.Pull = GPIO_PULLUP;
  HAL_GPIO_Init(GPIOE, &GPIO_InitStruct);

  /*Configure GPIO pin : BEEP_Pin */
  GPIO_InitStruct.Pin = BEEP_Pin;
  GPIO_InitStruct.Mode = GPIO_MODE_OUTPUT_PP;
  GPIO_InitStruct.Pull = GPIO_PULLDOWN;
  GPIO_InitStruct.Speed = GPIO_SPEED_FREQ_LOW;
  HAL_GPIO_Init(BEEP_GPIO_Port, &GPIO_InitStruct);

  /*Configure GPIO pins : PM2_CTRL_SD_Pin PM1_CTRL_SD_Pin */
  GPIO_InitStruct.Pin = PM2_CTRL_SD_Pin|PM1_CTRL_SD_Pin;
  GPIO_InitStruct.Mode = GPIO_MODE_OUTPUT_PP;
  GPIO_InitStruct.Pull = GPIO_PULLUP;
  GPIO_InitStruct.Speed = GPIO_SPEED_FREQ_LOW;
  HAL_GPIO_Init(GPIOF, &GPIO_InitStruct);

  /*Configure GPIO pin : PM1_ENC_SCK_Pin */
  GPIO_InitStruct.Pin = PM1_ENC_SCK_Pin;
  GPIO_InitStruct.Mode = GPIO_MODE_OUTPUT_PP;
  GPIO_InitStruct.Pull = GPIO_PULLUP;
  GPIO_InitStruct.Speed = GPIO_SPEED_FREQ_VERY_HIGH;
  HAL_GPIO_Init(PM1_ENC_SCK_GPIO_Port, &GPIO_InitStruct);

  /*Configure GPIO pin : PM1_ENC_DAT_Pin */
  GPIO_InitStruct.Pin = PM1_ENC_DAT_Pin;
  GPIO_InitStruct.Mode = GPIO_MODE_INPUT;
  GPIO_InitStruct.Pull = GPIO_NOPULL;
  HAL_GPIO_Init(PM1_ENC_DAT_GPIO_Port, &GPIO_InitStruct);

  /*Configure GPIO pin : PM2_ENC_SCK_Pin */
  GPIO_InitStruct.Pin = PM2_ENC_SCK_Pin;
  GPIO_InitStruct.Mode = GPIO_MODE_OUTPUT_PP;
  GPIO_InitStruct.Pull = GPIO_PULLUP;
  GPIO_InitStruct.Speed = GPIO_SPEED_FREQ_VERY_HIGH;
  HAL_GPIO_Init(PM2_ENC_SCK_GPIO_Port, &GPIO_InitStruct);

  /*Configure GPIO pin : PM2_ENC_DAT_Pin */
  GPIO_InitStruct.Pin = PM2_ENC_DAT_Pin;
  GPIO_InitStruct.Mode = GPIO_MODE_INPUT;
  GPIO_InitStruct.Pull = GPIO_NOPULL;
  HAL_GPIO_Init(PM2_ENC_DAT_GPIO_Port, &GPIO_InitStruct);

  /*Configure GPIO pins : LED0_Pin LED1_Pin */
  GPIO_InitStruct.Pin = LED0_Pin|LED1_Pin;
  GPIO_InitStruct.Mode = GPIO_MODE_OUTPUT_PP;
  GPIO_InitStruct.Pull = GPIO_PULLUP;
  GPIO_InitStruct.Speed = GPIO_SPEED_FREQ_LOW;
  HAL_GPIO_Init(GPIOE, &GPIO_InitStruct);

}

void Error_Handler(void)
{
  __disable_irq();
  while (1)
  {
  }
}
